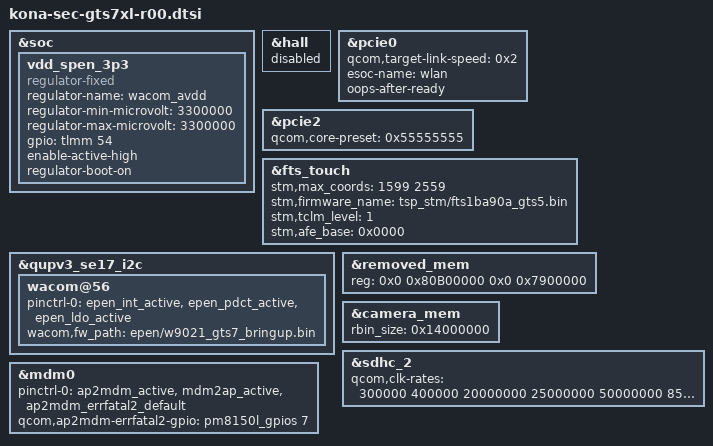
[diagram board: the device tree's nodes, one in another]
/* Copyright (c) 2019, The Linux Foundation. All rights reserved.
 *
 * This program is free software; you can redistribute it and/or modify
 * it under the terms of the GNU General Public License version 2 and
 * only version 2 as published by the Free Software Foundation.
 *
 * This program is distributed in the hope that it will be useful,
 * but WITHOUT ANY WARRANTY; without even the implied warranty of
 * MERCHANTABILITY or FITNESS FOR A PARTICULAR PURPOSE.  See the
 * GNU General Public License for more details.
 */

#include "kona-sec-gts7xl-pinctrl-r00.dtsi"
#include "../gts7l/kona-sec-gts7-pm-common.dtsi"
#include "../drivers/audio_gts7xl_common.dtsi"
#include "../drivers/input_gts7xl_common.dtsi"
#include "../drivers/displayport_gts7xl_r00.dtsi"
#include "../drivers/eif_gts7xl_common.dtsi"
#include "../drivers/battery-data-gts7xl-common.dtsi"
#include "../drivers/camera_sensor_gts7xl_r00.dtsi"
#include "../drivers/fingerprint-sensor_gts7xl_r00.dtsi"
#include "../drivers/bluetooth_gts7xl_common.dtsi"
#include "../drivers/kona-sec-gts7xl-grip-r00.dtsi"
#include "../drivers/kona-sec-gts7xl-display-r00.dtsi"
#include "../drivers/kona-sec-gts7l-sensor-r00.dtsi"

&soc {
	vdd_spen_3p3: vdd_spen_3p3 {
		compatible = "regulator-fixed";
		regulator-name = "wacom_avdd";
		regulator-min-microvolt = <3300000>;
		regulator-max-microvolt = <3300000>;
		gpio = <&tlmm 54 0>;
		enable-active-high;
		regulator-boot-on;
	};
};

&hall {
	status = "disabled";
};

&pcie0 {
	qcom,target-link-speed = <0x2>; /* limit to gen2 */
	esoc-name = "wlan";
	oops-after-ready;
};

&pcie2 {
	qcom,core-preset = <0x55555555>;
};

&fts_touch {
	stm,max_coords = <1599 2559>;	/* x y */
	stm,firmware_name = "tsp_stm/fts1ba90a_gts5.bin";
	stm,tclm_level = <1>;
	stm,afe_base = <0x0000>;
};

&qupv3_se17_i2c {
	wacom@56 {
		pinctrl-0 = <&epen_int_active &epen_pdct_active &epen_ldo_active>;
		wacom,fw_path = "epen/w9021_gts7_bringup.bin";
	};
};
&pcie0 {
	qcom,target-link-speed = <0x2>; /* limit to gen2 */
	esoc-name = "wlan";
	oops-after-ready;
};

&pcie2 {
	qcom,core-preset = <0x55555555>;
};

/* TZapp region */
&removed_mem {
	reg = <0x0 0x80B00000 0x0 0x7900000>;
};

&camera_mem {
	rbin_size = <0x14000000>;
};

&sdhc_2 {
	qcom,clk-rates = <300000 400000 20000000 25000000
		50000000 85714285 201500000>;
};

&mdm0 {
	pinctrl-0 = <&ap2mdm_active &mdm2ap_active &ap2mdm_errfatal2_default>;
	qcom,ap2mdm-errfatal2-gpio = <&pm8150l_gpios 7 0>;
};
